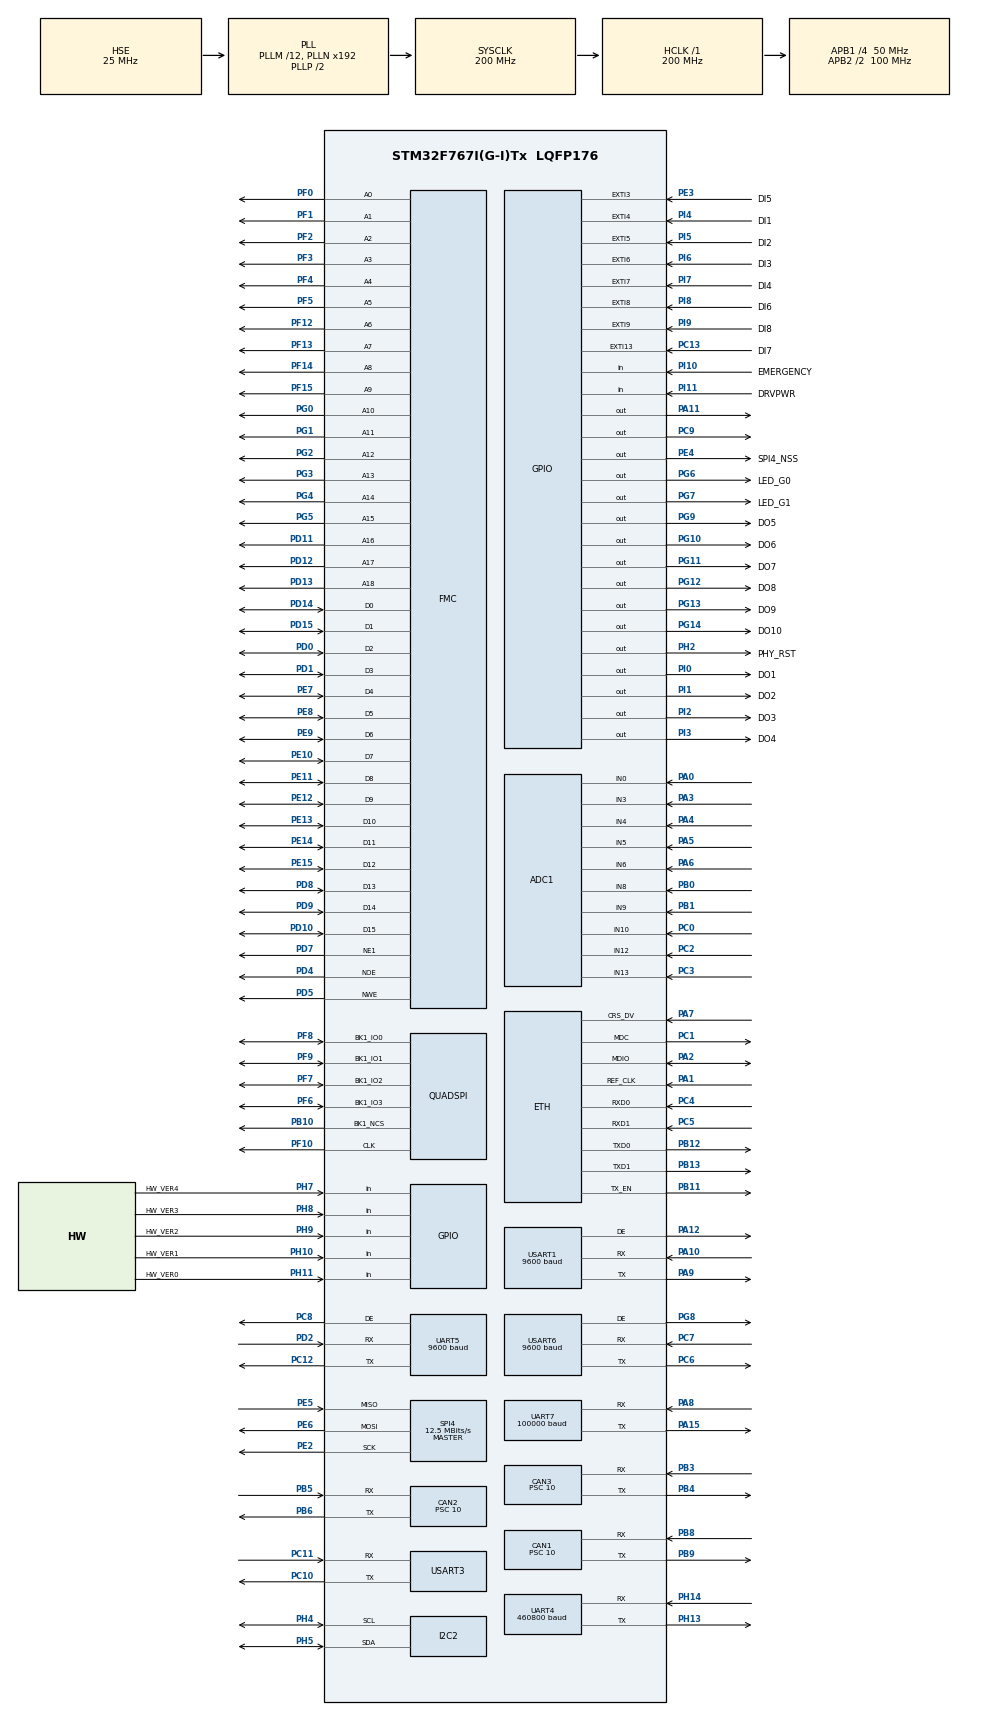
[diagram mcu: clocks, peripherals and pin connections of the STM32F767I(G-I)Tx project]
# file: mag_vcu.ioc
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ADC1.Channel-0\#ChannelRegularConversion=ADC_CHANNEL_13
ADC1.Channel-1\#ChannelRegularConversion=ADC_CHANNEL_0
ADC1.Channel-10\#ChannelRegularConversion=ADC_CHANNEL_TEMPSENSOR
ADC1.Channel-11\#ChannelRegularConversion=ADC_CHANNEL_VREFINT
ADC1.Channel-2\#ChannelRegularConversion=ADC_CHANNEL_10
ADC1.Channel-3\#ChannelRegularConversion=ADC_CHANNEL_12
ADC1.Channel-4\#ChannelRegularConversion=ADC_CHANNEL_5
ADC1.Channel-5\#ChannelRegularConversion=ADC_CHANNEL_6
ADC1.Channel-6\#ChannelRegularConversion=ADC_CHANNEL_3
ADC1.Channel-7\#ChannelRegularConversion=ADC_CHANNEL_4
ADC1.Channel-8\#ChannelRegularConversion=ADC_CHANNEL_8
ADC1.Channel-9\#ChannelRegularConversion=ADC_CHANNEL_9
ADC1.ContinuousConvMode=ENABLE
ADC1.DMAContinuousRequests=ENABLE
ADC1.EOCSelection=ADC_EOC_SEQ_CONV
ADC1.NbrOfConversion=12
ADC1.NbrOfConversionFlag=1
ADC1.Rank-0\#ChannelRegularConversion=1
ADC1.Rank-1\#ChannelRegularConversion=2
ADC1.Rank-10\#ChannelRegularConversion=11
ADC1.Rank-11\#ChannelRegularConversion=12
ADC1.Rank-2\#ChannelRegularConversion=3
ADC1.Rank-3\#ChannelRegularConversion=4
ADC1.Rank-4\#ChannelRegularConversion=5
ADC1.Rank-5\#ChannelRegularConversion=6
ADC1.Rank-6\#ChannelRegularConversion=7
ADC1.Rank-7\#ChannelRegularConversion=8
ADC1.Rank-8\#ChannelRegularConversion=9
ADC1.Rank-9\#ChannelRegularConversion=10
ADC1.SamplingTime-0\#ChannelRegularConversion=ADC_SAMPLETIME_56CYCLES
ADC1.SamplingTime-1\#ChannelRegularConversion=ADC_SAMPLETIME_56CYCLES
ADC1.SamplingTime-10\#ChannelRegularConversion=ADC_SAMPLETIME_56CYCLES
ADC1.SamplingTime-11\#ChannelRegularConversion=ADC_SAMPLETIME_56CYCLES
ADC1.SamplingTime-2\#ChannelRegularConversion=ADC_SAMPLETIME_56CYCLES
ADC1.SamplingTime-3\#ChannelRegularConversion=ADC_SAMPLETIME_56CYCLES
ADC1.SamplingTime-4\#ChannelRegularConversion=ADC_SAMPLETIME_56CYCLES
ADC1.SamplingTime-5\#ChannelRegularConversion=ADC_SAMPLETIME_56CYCLES
ADC1.SamplingTime-6\#ChannelRegularConversion=ADC_SAMPLETIME_56CYCLES
ADC1.SamplingTime-7\#ChannelRegularConversion=ADC_SAMPLETIME_56CYCLES
ADC1.SamplingTime-8\#ChannelRegularConversion=ADC_SAMPLETIME_56CYCLES
ADC1.SamplingTime-9\#ChannelRegularConversion=ADC_SAMPLETIME_56CYCLES
ADC1.ScanConvMode=ADC_SCAN_ENABLE
ADC1.master=1
CAN1.ABOM=ENABLE
CAN1.BS1=CAN_BS1_7TQ
CAN1.BS2=CAN_BS2_2TQ
CAN1.CalculateBaudRate=500000
CAN1.CalculateTimeBit=2000
CAN1.CalculateTimeQuantum=200.0
CAN1.NART=ENABLE
CAN1.Prescaler=10
CAN2.ABOM=ENABLE
CAN2.BS1=CAN_BS1_7TQ
CAN2.BS2=CAN_BS2_2TQ
CAN2.CalculateBaudRate=500000
CAN2.CalculateTimeBit=2000
CAN2.CalculateTimeQuantum=200.0
CAN2.NART=DISABLE
CAN2.Prescaler=10
CAN3.ABOM=ENABLE
CAN3.BS1=CAN_BS1_7TQ
CAN3.BS2=CAN_BS2_2TQ
CAN3.CalculateBaudRate=500000
CAN3.CalculateTimeBit=2000
CAN3.CalculateTimeQuantum=200.0
CAN3.NART=DISABLE
CAN3.Prescaler=10
CORTEX_M7.ART_ACCELERATOR_ENABLE=0
CORTEX_M7.AccessPermission-Cortex_Memory_Protection_Unit_Region0_Settings=MPU_REGION_FULL_ACCESS
CORTEX_M7.BaseAddress-Cortex_Memory_Protection_Unit_Region0_Settings=0x20020000
CORTEX_M7.CPU_DCache=Disabled
CORTEX_M7.CPU_ICache=Disabled
CORTEX_M7.Enable-Cortex_Memory_Protection_Unit_Region0_Settings=MPU_REGION_ENABLE
CORTEX_M7.IsBufferable-Cortex_Memory_Protection_Unit_Region0_Settings=MPU_ACCESS_NOT_BUFFERABLE
CORTEX_M7.IsCacheable-Cortex_Memory_Protection_Unit_Region0_Settings=MPU_ACCESS_CACHEABLE
CORTEX_M7.MPU_Control=__NULL
CORTEX_M7.Size-Cortex_Memory_Protection_Unit_Region0_Settings=MPU_REGION_SIZE_512KB
CORTEX_M7.TypeExtField-Cortex_Memory_Protection_Unit_Region0_Settings=MPU_TEX_LEVEL0
CORTEX_M7.default_mode_Activation=0
Dma.ADC1.3.Direction=DMA_PERIPH_TO_MEMORY
Dma.ADC1.3.FIFOMode=DMA_FIFOMODE_DISABLE
Dma.ADC1.3.Instance=DMA2_Stream0
Dma.ADC1.3.MemDataAlignment=DMA_MDATAALIGN_HALFWORD
Dma.ADC1.3.MemInc=DMA_MINC_ENABLE
Dma.ADC1.3.Mode=DMA_CIRCULAR
Dma.ADC1.3.PeriphDataAlignment=DMA_PDATAALIGN_HALFWORD
Dma.ADC1.3.PeriphInc=DMA_PINC_DISABLE
Dma.ADC1.3.Priority=DMA_PRIORITY_LOW
Dma.Request0=UART7_RX
Dma.Request1=USART3_RX
Dma.Request10=UART4_RX
Dma.Request2=USART3_TX
Dma.Request3=ADC1
Dma.Request4=USART6_RX
Dma.Request5=USART6_TX
Dma.Request6=USART1_RX
Dma.Request7=USART1_TX
Dma.Request8=UART5_RX
Dma.Request9=UART5_TX
Dma.UART4_RX.10.Direction=DMA_PERIPH_TO_MEMORY
Dma.UART4_RX.10.FIFOMode=DMA_FIFOMODE_DISABLE
Dma.UART4_RX.10.Instance=DMA1_Stream2
Dma.UART4_RX.10.MemDataAlignment=DMA_MDATAALIGN_BYTE
Dma.UART4_RX.10.MemInc=DMA_MINC_ENABLE
Dma.UART4_RX.10.Mode=DMA_NORMAL
Dma.UART4_RX.10.PeriphDataAlignment=DMA_PDATAALIGN_BYTE
Dma.UART4_RX.10.PeriphInc=DMA_PINC_DISABLE
Dma.UART4_RX.10.Priority=DMA_PRIORITY_LOW
Dma.UART5_RX.8.Direction=DMA_PERIPH_TO_MEMORY
Dma.UART5_RX.8.FIFOMode=DMA_FIFOMODE_DISABLE
Dma.UART5_RX.8.Instance=DMA1_Stream0
Dma.UART5_RX.8.MemDataAlignment=DMA_MDATAALIGN_BYTE
Dma.UART5_RX.8.MemInc=DMA_MINC_ENABLE
Dma.UART5_RX.8.Mode=DMA_NORMAL
Dma.UART5_RX.8.PeriphDataAlignment=DMA_PDATAALIGN_BYTE
Dma.UART5_RX.8.PeriphInc=DMA_PINC_DISABLE
Dma.UART5_RX.8.Priority=DMA_PRIORITY_LOW
Dma.UART5_TX.9.Direction=DMA_MEMORY_TO_PERIPH
Dma.UART5_TX.9.FIFOMode=DMA_FIFOMODE_DISABLE
Dma.UART5_TX.9.Instance=DMA1_Stream7
Dma.UART5_TX.9.MemDataAlignment=DMA_MDATAALIGN_BYTE
Dma.UART5_TX.9.MemInc=DMA_MINC_ENABLE
Dma.UART5_TX.9.Mode=DMA_NORMAL
Dma.UART5_TX.9.PeriphDataAlignment=DMA_PDATAALIGN_BYTE
Dma.UART5_TX.9.PeriphInc=DMA_PINC_DISABLE
Dma.UART5_TX.9.Priority=DMA_PRIORITY_LOW
Dma.UART7_RX.0.Direction=DMA_PERIPH_TO_MEMORY
Dma.UART7_RX.0.FIFOMode=DMA_FIFOMODE_DISABLE
Dma.UART7_RX.0.Instance=DMA1_Stream3
Dma.UART7_RX.0.MemDataAlignment=DMA_MDATAALIGN_BYTE
Dma.UART7_RX.0.MemInc=DMA_MINC_ENABLE
Dma.UART7_RX.0.Mode=DMA_NORMAL
Dma.UART7_RX.0.PeriphDataAlignment=DMA_PDATAALIGN_BYTE
Dma.UART7_RX.0.PeriphInc=DMA_PINC_DISABLE
Dma.UART7_RX.0.Priority=DMA_PRIORITY_LOW
Dma.USART1_RX.6.Direction=DMA_PERIPH_TO_MEMORY
Dma.USART1_RX.6.FIFOMode=DMA_FIFOMODE_DISABLE
Dma.USART1_RX.6.Instance=DMA2_Stream2
Dma.USART1_RX.6.MemDataAlignment=DMA_MDATAALIGN_BYTE
Dma.USART1_RX.6.MemInc=DMA_MINC_ENABLE
Dma.USART1_RX.6.Mode=DMA_NORMAL
Dma.USART1_RX.6.PeriphDataAlignment=DMA_PDATAALIGN_BYTE
Dma.USART1_RX.6.PeriphInc=DMA_PINC_DISABLE
Dma.USART1_RX.6.Priority=DMA_PRIORITY_LOW
Dma.USART1_TX.7.Direction=DMA_MEMORY_TO_PERIPH
Dma.USART1_TX.7.FIFOMode=DMA_FIFOMODE_DISABLE
Dma.USART1_TX.7.Instance=DMA2_Stream7
Dma.USART1_TX.7.MemDataAlignment=DMA_MDATAALIGN_BYTE
Dma.USART1_TX.7.MemInc=DMA_MINC_ENABLE
Dma.USART1_TX.7.Mode=DMA_NORMAL
Dma.USART1_TX.7.PeriphDataAlignment=DMA_PDATAALIGN_BYTE
Dma.USART1_TX.7.PeriphInc=DMA_PINC_DISABLE
Dma.USART1_TX.7.Priority=DMA_PRIORITY_LOW
Dma.USART3_RX.1.Direction=DMA_PERIPH_TO_MEMORY
Dma.USART3_RX.1.FIFOMode=DMA_FIFOMODE_DISABLE
Dma.USART3_RX.1.Instance=DMA1_Stream1
Dma.USART3_RX.1.MemDataAlignment=DMA_MDATAALIGN_BYTE
Dma.USART3_RX.1.MemInc=DMA_MINC_ENABLE
Dma.USART3_RX.1.Mode=DMA_NORMAL
Dma.USART3_RX.1.PeriphDataAlignment=DMA_PDATAALIGN_BYTE
Dma.USART3_RX.1.PeriphInc=DMA_PINC_DISABLE
Dma.USART3_RX.1.Priority=DMA_PRIORITY_LOW
Dma.USART3_TX.2.Direction=DMA_MEMORY_TO_PERIPH
Dma.USART3_TX.2.FIFOMode=DMA_FIFOMODE_DISABLE
Dma.USART3_TX.2.Instance=DMA1_Stream4
Dma.USART3_TX.2.MemDataAlignment=DMA_MDATAALIGN_BYTE
Dma.USART3_TX.2.MemInc=DMA_MINC_ENABLE
Dma.USART3_TX.2.Mode=DMA_NORMAL
Dma.USART3_TX.2.PeriphDataAlignment=DMA_PDATAALIGN_BYTE
Dma.USART3_TX.2.PeriphInc=DMA_PINC_DISABLE
Dma.USART3_TX.2.Priority=DMA_PRIORITY_LOW
Dma.USART6_RX.4.Direction=DMA_PERIPH_TO_MEMORY
Dma.USART6_RX.4.FIFOMode=DMA_FIFOMODE_DISABLE
Dma.USART6_RX.4.Instance=DMA2_Stream1
Dma.USART6_RX.4.MemDataAlignment=DMA_MDATAALIGN_BYTE
Dma.USART6_RX.4.MemInc=DMA_MINC_ENABLE
Dma.USART6_RX.4.Mode=DMA_NORMAL
Dma.USART6_RX.4.PeriphDataAlignment=DMA_PDATAALIGN_BYTE
Dma.USART6_RX.4.PeriphInc=DMA_PINC_DISABLE
Dma.USART6_RX.4.Priority=DMA_PRIORITY_LOW
Dma.USART6_TX.5.Direction=DMA_MEMORY_TO_PERIPH
Dma.USART6_TX.5.FIFOMode=DMA_FIFOMODE_DISABLE
Dma.USART6_TX.5.Instance=DMA2_Stream6
Dma.USART6_TX.5.MemDataAlignment=DMA_MDATAALIGN_BYTE
Dma.USART6_TX.5.MemInc=DMA_MINC_ENABLE
Dma.USART6_TX.5.Mode=DMA_NORMAL
Dma.USART6_TX.5.PeriphDataAlignment=DMA_PDATAALIGN_BYTE
Dma.USART6_TX.5.PeriphInc=DMA_PINC_DISABLE
Dma.USART6_TX.5.Priority=DMA_PRIORITY_LOW
ETH.ETH_RX_DESC_CNT=8
ETH.ETH_TX_DESC_CNT=8
ETH.MediaInterface=HAL_ETH_RMII_MODE
FMC.ExtendedAddressSetupTime1=5
FMC.ExtendedBusTurnAroundDuration1=3
FMC.ExtendedDataSetupTime1=3
FMC.ExtendedMode1=FMC_EXTENDED_MODE_ENABLE
FMC.WriteOperation1=FMC_WRITE_OPERATION_ENABLE
I2C2.Timing=0x00C0EAFF
IWDG.Prescaler=IWDG_PRESCALER_256
LPTIM1.ClockPrescaler=LPTIM_PRESCALER_DIV2
LPTIM1.UpdateMode=LPTIM_UPDATE_ENDOFPERIOD
Mcu.Family=STM32F7
Mcu.Name=STM32F767I(G-I)Tx
Mcu.Package=LQFP176
NVIC.ADC_IRQn=true\:5\:0\:true\:false\:true\:true\:true\:true
NVIC.CAN1_RX0_IRQn=true\:5\:0\:true\:false\:true\:true\:true\:true
NVIC.CAN1_TX_IRQn=true\:0\:0\:false\:false\:true\:true\:true\:true
NVIC.CAN2_RX0_IRQn=true\:5\:0\:true\:false\:true\:true\:true\:true
NVIC.CAN2_TX_IRQn=true\:0\:0\:false\:false\:true\:true\:true\:true
NVIC.CAN3_RX0_IRQn=true\:5\:0\:true\:false\:true\:true\:true\:true
NVIC.CAN3_TX_IRQn=true\:0\:0\:false\:false\:true\:true\:true\:true
NVIC.DMA1_Stream0_IRQn=true\:0\:0\:false\:false\:true\:false\:true\:true
NVIC.DMA1_Stream1_IRQn=true\:5\:0\:true\:false\:true\:false\:true\:true
NVIC.DMA1_Stream2_IRQn=true\:0\:0\:false\:false\:true\:false\:true\:true
NVIC.DMA1_Stream3_IRQn=true\:5\:0\:true\:false\:true\:false\:true\:true
NVIC.DMA1_Stream4_IRQn=true\:5\:0\:true\:false\:true\:false\:true\:true
NVIC.DMA1_Stream7_IRQn=true\:0\:0\:false\:false\:true\:false\:true\:true
NVIC.DMA2_Stream0_IRQn=true\:5\:0\:true\:false\:true\:false\:true\:true
NVIC.DMA2_Stream1_IRQn=true\:5\:0\:true\:false\:true\:false\:true\:true
NVIC.DMA2_Stream2_IRQn=true\:5\:0\:true\:false\:true\:false\:true\:true
NVIC.DMA2_Stream6_IRQn=true\:5\:0\:true\:false\:true\:false\:true\:true
NVIC.DMA2_Stream7_IRQn=true\:5\:0\:true\:false\:true\:false\:true\:true
NVIC.ETH_IRQn=true\:5\:0\:true\:false\:true\:true\:true\:true
NVIC.EXTI15_10_IRQn=true\:0\:0\:false\:false\:true\:true\:true\:true
NVIC.EXTI3_IRQn=true\:0\:0\:false\:false\:true\:true\:true\:true
NVIC.EXTI4_IRQn=true\:0\:0\:false\:false\:true\:true\:true\:true
NVIC.EXTI9_5_IRQn=true\:0\:0\:false\:false\:true\:true\:true\:true
NVIC.I2C2_EV_IRQn=true\:5\:0\:true\:false\:true\:true\:true\:true
NVIC.PriorityGroup=NVIC_PRIORITYGROUP_4
NVIC.QUADSPI_IRQn=true\:5\:0\:true\:false\:true\:true\:true\:true
NVIC.SPI4_IRQn=true\:5\:0\:true\:false\:true\:true\:true\:true
NVIC.TIM1_UP_TIM10_IRQn=true\:5\:0\:true\:false\:true\:true\:true\:true
NVIC.TIM6_DAC_IRQn=true\:15\:0\:true\:false\:true\:false\:true\:true
NVIC.TimeBase=TIM6_DAC_IRQn
NVIC.TimeBaseIP=TIM6
NVIC.UART4_IRQn=true\:5\:0\:true\:false\:true\:true\:true\:true
NVIC.UART5_IRQn=true\:0\:0\:false\:false\:true\:true\:true\:true
NVIC.UART7_IRQn=true\:5\:0\:true\:false\:true\:true\:true\:true
NVIC.USART1_IRQn=true\:5\:0\:true\:false\:true\:true\:true\:true
NVIC.USART3_IRQn=true\:5\:0\:true\:false\:true\:true\:true\:true
NVIC.USART6_IRQn=true\:5\:0\:true\:false\:true\:true\:true\:true
PA0/WKUP.Signal=ADCx_IN0
PA1.GPIO_PuPd=GPIO_PULLUP
PA1.Mode=RMII
PA1.Signal=ETH_REF_CLK
PA10.Mode=Asynchronous
PA10.Signal=USART1_RX
PA11.GPIO_ModeDefaultOutputPP=GPIO_MODE_OUTPUT_OD
PA11.GPIO_PuPd=GPIO_NOPULL
PA11.PinState=GPIO_PIN_SET
PA11.Signal=GPIO_Output
PA12.GPIO_PuPd=GPIO_PULLUP
PA12.Mode=Hardware Flow Control (RS485)
PA12.Signal=USART1_DE
PA13.Mode=Serial_Wire
PA13.Signal=SYS_JTMS-SWDIO
PA14.Mode=Serial_Wire
PA14.Signal=SYS_JTCK-SWCLK
PA15.GPIO_PuPd=GPIO_PULLUP
PA15.Mode=Asynchronous
PA15.Signal=UART7_TX
PA2.Mode=RMII
PA2.Signal=ETH_MDIO
PA3.Signal=ADCx_IN3
PA4.Signal=ADCx_IN4
PA5.Signal=ADCx_IN5
PA6.Signal=ADCx_IN6
PA7.GPIO_PuPd=GPIO_PULLUP
PA7.Mode=RMII
PA7.Signal=ETH_CRS_DV
PA8.Mode=Asynchronous
PA8.Signal=UART7_RX
PA9.GPIO_PuPd=GPIO_PULLUP
PA9.Mode=Asynchronous
PA9.Signal=USART1_TX
PB0.Signal=ADCx_IN8
PB1.Signal=ADCx_IN9
PB10.GPIO_PuPd=GPIO_NOPULL
PB10.Mode=Single Bank 1
PB10.Signal=QUADSPI_BK1_NCS
PB11.GPIO_PuPd=GPIO_PULLUP
PB11.Mode=RMII
PB11.Signal=ETH_TX_EN
PB12.GPIO_PuPd=GPIO_PULLUP
PB12.Mode=RMII
PB12.Signal=ETH_TXD0
PB13.GPIO_PuPd=GPIO_PULLUP
PB13.Mode=RMII
PB13.Signal=ETH_TXD1
PB3.Mode=CAN_Activate
PB3.Signal=CAN3_RX
PB4.GPIO_PuPd=GPIO_PULLUP
PB4.Mode=CAN_Activate
PB4.Signal=CAN3_TX
PB5.Mode=CAN_Activate
PB5.Signal=CAN2_RX
PB6.GPIO_PuPd=GPIO_PULLUP
PB6.Mode=CAN_Activate
PB6.Signal=CAN2_TX
PB8.Mode=CAN_Activate
PB8.Signal=CAN1_RX
PB9.GPIO_PuPd=GPIO_PULLUP
PB9.Mode=CAN_Activate
PB9.Signal=CAN1_TX
PC0.Signal=ADCx_IN10
PC1.GPIO_PuPd=GPIO_PULLUP
PC1.Mode=RMII
PC1.Signal=ETH_MDC
PC10.GPIO_PuPd=GPIO_PULLUP
PC10.Mode=Asynchronous
PC10.Signal=USART3_TX
PC11.Mode=Asynchronous
PC11.Signal=USART3_RX
PC12.GPIO_PuPd=GPIO_PULLUP
PC12.Mode=Asynchronous
PC12.Signal=UART5_TX
PC13.GPIO_Label=DI7
PC13.GPIO_ModeDefaultEXTI=GPIO_MODE_IT_RISING_FALLING
PC13.Signal=GPXTI13
PC14/OSC32_IN.Mode=LSE-External-Oscillator
PC14/OSC32_IN.Signal=RCC_OSC32_IN
PC15/OSC32_OUT.Mode=LSE-External-Oscillator
PC15/OSC32_OUT.Signal=RCC_OSC32_OUT
PC2.Signal=ADCx_IN12
PC3.Signal=ADCx_IN13
PC4.Mode=RMII
PC4.Signal=ETH_RXD0
PC5.Mode=RMII
PC5.Signal=ETH_RXD1
PC6.GPIO_PuPd=GPIO_PULLUP
PC6.Mode=Asynchronous
PC6.Signal=USART6_TX
PC7.Mode=Asynchronous
PC7.Signal=USART6_RX
PC8.GPIO_PuPd=GPIO_PULLUP
PC8.Mode=Hardware Flow Control (RS485)
PC8.Signal=UART5_DE
PC9.GPIO_ModeDefaultOutputPP=GPIO_MODE_OUTPUT_OD
PC9.GPIO_PuPd=GPIO_NOPULL
PC9.PinState=GPIO_PIN_SET
PC9.Signal=GPIO_Output
PD0.Signal=FMC_D2_DA2
PD1.Signal=FMC_D3_DA3
PD10.Signal=FMC_D15_DA15
PD11.Signal=FMC_A16_CLE
PD12.Signal=FMC_A17_ALE
PD13.Signal=FMC_A18
PD14.Signal=FMC_D0_DA0
PD15.Signal=FMC_D1_DA1
PD2.Mode=Asynchronous
PD2.Signal=UART5_RX
PD4.Signal=FMC_NOE
PD5.Signal=FMC_NWE
PD7.Mode=NorPsramChipSelect1_1
PD7.Signal=FMC_NE1
PD8.Signal=FMC_D13_DA13
PD9.Signal=FMC_D14_DA14
PE10.Signal=FMC_D7_DA7
PE11.Signal=FMC_D8_DA8
PE12.Signal=FMC_D9_DA9
PE13.Signal=FMC_D10_DA10
PE14.Signal=FMC_D11_DA11
PE15.Signal=FMC_D12_DA12
PE2.GPIO_PuPd=GPIO_NOPULL
PE2.Mode=Full_Duplex_Master
PE2.Signal=SPI4_SCK
PE3.GPIO_Label=DI5
PE3.GPIO_ModeDefaultEXTI=GPIO_MODE_IT_RISING_FALLING
PE3.Signal=GPXTI3
PE4.GPIO_Label=SPI4_NSS
PE4.GPIO_ModeDefaultOutputPP=GPIO_MODE_OUTPUT_PP
PE4.GPIO_PuPd=GPIO_NOPULL
PE4.GPIO_Speed=GPIO_SPEED_FREQ_VERY_HIGH
PE4.PinState=GPIO_PIN_SET
PE4.Signal=GPIO_Output
PE5.Mode=Full_Duplex_Master
PE5.Signal=SPI4_MISO
PE6.GPIO_PuPd=GPIO_NOPULL
PE6.Mode=Full_Duplex_Master
PE6.Signal=SPI4_MOSI
PE7.Signal=FMC_D4_DA4
PE8.Signal=FMC_D5_DA5
PE9.Signal=FMC_D6_DA6
PF0.Signal=FMC_A0
PF1.Signal=FMC_A1
PF10.GPIO_PuPd=GPIO_PULLUP
PF10.Mode=Single Bank 1
PF10.Signal=QUADSPI_CLK
PF12.Signal=FMC_A6
PF13.Signal=FMC_A7
PF14.Signal=FMC_A8
PF15.Signal=FMC_A9
PF2.Signal=FMC_A2
PF3.Signal=FMC_A3
PF4.Signal=FMC_A4
PF5.Signal=FMC_A5
PF6.GPIO_PuPd=GPIO_PULLUP
PF6.Mode=Single Bank 1
PF6.Signal=QUADSPI_BK1_IO3
PF7.GPIO_PuPd=GPIO_PULLUP
PF7.Mode=Single Bank 1
PF7.Signal=QUADSPI_BK1_IO2
PF8.GPIO_PuPd=GPIO_PULLUP
PF8.Mode=Single Bank 1
PF8.Signal=QUADSPI_BK1_IO0
PF9.GPIO_PuPd=GPIO_PULLUP
PF9.Mode=Single Bank 1
PF9.Signal=QUADSPI_BK1_IO1
PG0.Signal=FMC_A10
PG1.Signal=FMC_A11
PG10.GPIO_Label=DO6
PG10.Signal=GPIO_Output
PG11.GPIO_Label=DO7
PG11.Signal=GPIO_Output
PG12.GPIO_Label=DO8
PG12.Signal=GPIO_Output
PG13.GPIO_Label=DO9
PG13.PinState=GPIO_PIN_SET
PG13.Signal=GPIO_Output
PG14.GPIO_Label=DO10
PG14.PinState=GPIO_PIN_SET
PG14.Signal=GPIO_Output
PG2.Signal=FMC_A12
PG3.Signal=FMC_A13
PG4.Signal=FMC_A14_BA0
PG5.Signal=FMC_A15_BA1
PG6.GPIO_Label=LED_G0
PG6.GPIO_ModeDefaultOutputPP=GPIO_MODE_OUTPUT_OD
PG6.GPIO_PuPd=GPIO_NOPULL
PG6.PinState=GPIO_PIN_SET
PG6.Signal=GPIO_Output
PG7.GPIO_Label=LED_G1
PG7.GPIO_ModeDefaultOutputPP=GPIO_MODE_OUTPUT_OD
PG7.GPIO_PuPd=GPIO_NOPULL
PG7.PinState=GPIO_PIN_SET
PG7.Signal=GPIO_Output
PG8.GPIO_PuPd=GPIO_PULLUP
PG8.Mode=Hardware Flow Control (RS485)
PG8.Signal=USART6_DE
PG9.GPIO_Label=DO5
PG9.Signal=GPIO_Output
PH0/OSC_IN.Mode=HSE-External-Oscillator
PH0/OSC_IN.Signal=RCC_OSC_IN
PH1/OSC_OUT.Mode=HSE-External-Oscillator
PH1/OSC_OUT.Signal=RCC_OSC_OUT
PH10.GPIO_Label=HW_VER1
PH10.Signal=GPIO_Input
PH11.GPIO_Label=HW_VER0
PH11.Signal=GPIO_Input
PH13.GPIO_PuPd=GPIO_PULLUP
PH13.Mode=Asynchronous
PH13.Signal=UART4_TX
PH14.Mode=Asynchronous
PH14.Signal=UART4_RX
PH2.GPIO_Label=PHY_RST
PH2.GPIO_ModeDefaultOutputPP=GPIO_MODE_OUTPUT_OD
PH2.GPIO_PuPd=GPIO_NOPULL
PH2.PinState=GPIO_PIN_SET
PH2.Signal=GPIO_Output
PH4.Mode=I2C
PH4.Signal=I2C2_SCL
PH5.Mode=I2C
PH5.Signal=I2C2_SDA
PH7.GPIO_Label=HW_VER4
PH7.Signal=GPIO_Input
PH8.GPIO_Label=HW_VER3
PH8.Signal=GPIO_Input
PH9.GPIO_Label=HW_VER2
PH9.Signal=GPIO_Input
PI0.GPIO_Label=DO1
PI0.GPIO_ModeDefaultOutputPP=GPIO_MODE_OUTPUT_OD
PI0.GPIO_PuPd=GPIO_NOPULL
PI0.PinState=GPIO_PIN_SET
PI0.Signal=GPIO_Output
PI1.GPIO_Label=DO2
PI1.GPIO_ModeDefaultOutputPP=GPIO_MODE_OUTPUT_OD
PI1.GPIO_PuPd=GPIO_NOPULL
PI1.PinState=GPIO_PIN_RESET
PI1.Signal=GPIO_Output
PI10.GPIO_Label=EMERGENCY
PI10.Signal=GPIO_Input
PI11.GPIO_Label=DRVPWR
PI11.Signal=GPIO_Input
PI2.GPIO_Label=DO3
PI2.GPIO_ModeDefaultOutputPP=GPIO_MODE_OUTPUT_OD
PI2.GPIO_PuPd=GPIO_NOPULL
PI2.PinState=GPIO_PIN_SET
PI2.Signal=GPIO_Output
PI3.GPIO_Label=DO4
PI3.GPIO_ModeDefaultOutputPP=GPIO_MODE_OUTPUT_OD
PI3.GPIO_PuPd=GPIO_NOPULL
PI3.PinState=GPIO_PIN_SET
PI3.Signal=GPIO_Output
PI4.GPIO_Label=DI1
PI4.GPIO_ModeDefaultEXTI=GPIO_MODE_IT_RISING_FALLING
PI4.Signal=GPXTI4
PI5.GPIO_Label=DI2
PI5.GPIO_ModeDefaultEXTI=GPIO_MODE_IT_RISING_FALLING
PI5.Signal=GPXTI5
PI6.GPIO_Label=DI3
PI6.GPIO_ModeDefaultEXTI=GPIO_MODE_IT_RISING_FALLING
PI6.Signal=GPXTI6
PI7.GPIO_Label=DI4
PI7.GPIO_ModeDefaultEXTI=GPIO_MODE_IT_RISING_FALLING
PI7.Signal=GPXTI7
PI8.GPIO_Label=DI6
PI8.GPIO_ModeDefaultEXTI=GPIO_MODE_IT_RISING_FALLING
PI8.Signal=GPXTI8
PI9.GPIO_Label=DI8
PI9.GPIO_ModeDefaultEXTI=GPIO_MODE_IT_RISING_FALLING
PI9.Signal=GPXTI9
ProjectManager.HeapSize=0x200
ProjectManager.StackSize=0x6000
ProjectManager.TargetToolchain=CMake
QUADSPI.ChipSelectHighTime=QSPI_CS_HIGH_TIME_6_CYCLE
QUADSPI.ClockPrescaler=4
QUADSPI.FifoThreshold=4
QUADSPI.FlashSize=24-1
QUADSPI.SampleShifting=QSPI_SAMPLE_SHIFTING_HALFCYCLE
RCC.AHBFreq_Value=200000000
RCC.APB1CLKDivider=RCC_HCLK_DIV4
RCC.APB1Freq_Value=50000000
RCC.APB1TimFreq_Value=100000000
RCC.APB2CLKDivider=RCC_HCLK_DIV2
RCC.APB2Freq_Value=100000000
RCC.APB2TimFreq_Value=200000000
RCC.CortexFreq_Value=200000000
RCC.HCLKFreq_Value=200000000
RCC.HSE_VALUE=25000000
RCC.HSI_VALUE=16000000
RCC.PLLM=12
RCC.PLLQ=9
RCC.PLLSourceVirtual=RCC_PLLSOURCE_HSE
RCC.SYSCLKFreq_VALUE=200000000
RCC.SYSCLKSource=RCC_SYSCLKSOURCE_PLLCLK
RCC.USBFreq_Value=44444444.44444445
RCC.VCOOutputFreq_Value=400000000
SH.ADCx_IN0.0=ADC1_IN0,IN0
SH.ADCx_IN10.0=ADC1_IN10,IN10
SH.ADCx_IN12.0=ADC1_IN12,IN12
SH.ADCx_IN13.0=ADC1_IN13,IN13
SH.ADCx_IN3.0=ADC1_IN3,IN3
SH.ADCx_IN4.0=ADC1_IN4,IN4
SH.ADCx_IN5.0=ADC1_IN5,IN5
SH.ADCx_IN6.0=ADC1_IN6,IN6
SH.ADCx_IN8.0=ADC1_IN8,IN8
SH.ADCx_IN9.0=ADC1_IN9,IN9
SH.FMC_A0.0=FMC_A0,19b-a1
SH.FMC_A1.0=FMC_A1,19b-a1
SH.FMC_A10.0=FMC_A10,19b-a1
SH.FMC_A11.0=FMC_A11,19b-a1
SH.FMC_A12.0=FMC_A12,19b-a1
SH.FMC_A13.0=FMC_A13,19b-a1
SH.FMC_A14_BA0.0=FMC_A14,19b-a1
SH.FMC_A15_BA1.0=FMC_A15,19b-a1
SH.FMC_A16_CLE.0=FMC_A16,19b-a1
SH.FMC_A17_ALE.0=FMC_A17,19b-a1
SH.FMC_A18.0=FMC_A18,19b-a1
SH.FMC_A2.0=FMC_A2,19b-a1
SH.FMC_A3.0=FMC_A3,19b-a1
SH.FMC_A4.0=FMC_A4,19b-a1
SH.FMC_A5.0=FMC_A5,19b-a1
SH.FMC_A6.0=FMC_A6,19b-a1
SH.FMC_A7.0=FMC_A7,19b-a1
SH.FMC_A8.0=FMC_A8,19b-a1
SH.FMC_A9.0=FMC_A9,19b-a1
SH.FMC_D0_DA0.0=FMC_D0,16b-d1
SH.FMC_D10_DA10.0=FMC_D10,16b-d1
SH.FMC_D11_DA11.0=FMC_D11,16b-d1
SH.FMC_D12_DA12.0=FMC_D12,16b-d1
SH.FMC_D13_DA13.0=FMC_D13,16b-d1
SH.FMC_D14_DA14.0=FMC_D14,16b-d1
SH.FMC_D15_DA15.0=FMC_D15,16b-d1
SH.FMC_D1_DA1.0=FMC_D1,16b-d1
SH.FMC_D2_DA2.0=FMC_D2,16b-d1
SH.FMC_D3_DA3.0=FMC_D3,16b-d1
SH.FMC_D4_DA4.0=FMC_D4,16b-d1
SH.FMC_D5_DA5.0=FMC_D5,16b-d1
SH.FMC_D6_DA6.0=FMC_D6,16b-d1
SH.FMC_D7_DA7.0=FMC_D7,16b-d1
SH.FMC_D8_DA8.0=FMC_D8,16b-d1
SH.FMC_D9_DA9.0=FMC_D9,16b-d1
SH.FMC_NOE.0=FMC_NOE,Sram1
SH.FMC_NWE.0=FMC_NWE,Sram1
SPI4.BaudRatePrescaler=SPI_BAUDRATEPRESCALER_8
SPI4.CLKPhase=SPI_PHASE_2EDGE
SPI4.CLKPolarity=SPI_POLARITY_HIGH
SPI4.CalculateBaudRate=12.5 MBits/s
SPI4.DataSize=SPI_DATASIZE_8BIT
SPI4.Direction=SPI_DIRECTION_2LINES
SPI4.Mode=SPI_MODE_MASTER
SPI4.VirtualType=VM_MASTER
STMicroelectronics.X-CUBE-ALGOBUILD.1.3.0.LibraryCcDSPOoLibraryJjDSPOoLibrary=true
TIM1.AutoReloadPreload=TIM_AUTORELOAD_PRELOAD_ENABLE
TIM1.ClockDivision=TIM_CLOCKDIVISION_DIV2
TIM1.Period=100
TIM1.Prescaler=100-1
TIM2.AutoReloadPreload=TIM_AUTORELOAD_PRELOAD_ENABLE
TIM2.Period=1000000
TIM2.Prescaler=100-1
TIM2.TIM_MasterOutputTrigger=TIM_TRGO_UPDATE
TIM2.TIM_MasterSlaveMode=TIM_MASTERSLAVEMODE_ENABLE
UART4.BaudRate=460800
UART5.BaudRate=9600
UART7.BaudRate=100000
UART7.DMADisableonRxErrorParam=UART_ADVFEATURE_DMA_ENABLEONRXERROR
UART7.Mode=MODE_RX
UART7.OverrunDisableParam=UART_ADVFEATURE_OVERRUN_ENABLE
UART7.Parity=PARITY_EVEN
UART7.StopBits=UART_STOPBITS_2
UART7.WordLength=WORDLENGTH_9B
USART1.BaudRate=9600
USART1.VirtualMode-Asynchronous=VM_ASYNC
USART1.VirtualMode-Hardware\ Flow\ Control\ (RS485)=VM_ASYNC
USART3.VirtualMode-Asynchronous=VM_ASYNC
USART6.BaudRate=9600
USART6.VirtualMode-Asynchronous=VM_ASYNC
USART6.VirtualMode-Hardware\ Flow\ Control\ (RS485)=VM_ASYNC
VP_ADC1_TempSens_Input.Mode=IN-TempSens
VP_ADC1_Vref_Input.Mode=IN-Vrefint
VP_CRC_VS_CRC.Mode=CRC_Activate
VP_IWDG_VS_IWDG.Mode=IWDG_Activate
VP_LPTIM1_VS_LPTIM_counterModeInternalClock.Mode=Counts__internal_clock_event_00
VP_RNG_VS_RNG.Mode=RNG_Activate
VP_STMicroelectronics.X-CUBE-ALGOBUILD_VS_DSPOoLibraryJjLibrary_1.3.0_1.3.0.Mode=DSPOoLibraryJjLibrary
VP_SYS_VS_tim6.Mode=TIM6
VP_TIM1_VS_ClockSourceINT.Mode=Internal
VP_TIM2_VS_ClockSourceINT.Mode=Internal
VP_TIM5_VS_ClockSourceITR.Mode=TriggerSource_ITR0
VP_TIM5_VS_ControllerModeClock.Mode=Clock Mode
board=custom

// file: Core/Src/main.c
/* USER CODE BEGIN Header */
/**
  ******************************************************************************
  * @file           : main.c
  * @brief          : Main program body
  ******************************************************************************
  * @attention
  *
  * Copyright (c) 2025 STMicroelectronics.
  * All rights reserved.
  *
  * This software is licensed under terms that can be found in the LICENSE file
  * in the root directory of this software component.
  * If no LICENSE file comes with this software, it is provided AS-IS.
  *
  ******************************************************************************
  */
/* USER CODE END Header */
#include "main.h"
#include "adc.h"
#include "can.h"
#include "crc.h"
#include "dma.h"
#include "eth.h"
#include "i2c.h"
#include "iwdg.h"
#include "lptim.h"
#include "quadspi.h"
#include "rng.h"
#include "spi.h"
#include "tim.h"
#include "tx_api.h"
#include "usart.h"
#include "gpio.h"
#include "fmc.h"

/* USER CODE BEGIN Includes */
#include "tx_thread.h"
#include "tx_initialize.h"
#include "thread_init.h"
#include "flash_nor.h"
/* USER CODE END Includes */

/* USER CODE BEGIN PTD */
uint32_t HAL_GetTick (void)
{
static uint32_t ticks = 0U;
uint32_t i;
if (TX_THREAD_GET_SYSTEM_STATE() == TX_INITIALIZE_IS_FINISHED)
{
return ((uint32_t)_tx_time_get());
}
/* ??ThreadX?????,?????? */
for (i = (SystemCoreClock >> 14U); i > 0U; i--)
{
__NOP(); __NOP(); __NOP(); __NOP(); __NOP(); __NOP();
__NOP(); __NOP(); __NOP(); __NOP(); __NOP(); __NOP();
}
return ++ticks;
}

void sleep_s(uint32_t s)
{
  tx_thread_sleep(s*1000);
}
void sleep_ms(uint32_t ms)
{
	tx_thread_sleep(ms);
}
void sleep_us(uint32_t us)
{
	tx_thread_sleep(us/1000u);
}

/* USER CODE END PTD */

void SystemClock_Config(void);

/* USER CODE BEGIN 0 */
// thread init
TX_THREAD thread_init_block;
#define THREAD_INIT_STACK_SIZE 				4096u
uint64_t thread_init_stack[THREAD_INIT_STACK_SIZE/8];
#define THREAD_INIT_PRIO							28u

/******************************tx kits define**************************************/

// pool

// sem
TX_SEMAPHORE  sem_socket_connected;

static void tx_pool_create(void)
{

}

static void tx_sem_create(void)
{
  tx_semaphore_create(&sem_socket_connected, "sem_socket_connected", 0);
}

void  tx_application_define(void *first_unused_memory)
{
  norflash_init();
	tx_pool_create();
  tx_sem_create();

  tx_thread_create(&thread_init_block,
                  "init",
                  thread_init,
                  0,
                  &thread_init_stack[0],
                  THREAD_INIT_STACK_SIZE,
                  THREAD_INIT_PRIO,
                  THREAD_INIT_PRIO,
                  TX_NO_TIME_SLICE,
                  TX_AUTO_START);
}
/* USER CODE END 0 */

int main(void)
{

  /* MCU Configuration--------------------------------------------------------*/

  /* Reset of all peripherals, Initializes the Flash interface and the Systick. */
  HAL_Init();

  /* Configure the system clock */
  SystemClock_Config();

  /* Initialize all configured peripherals */
  MX_GPIO_Init();
  MX_DMA_Init();
  MX_CAN1_Init();
  MX_CAN2_Init();
  MX_CAN3_Init();
  MX_I2C2_Init();
  MX_SPI4_Init();
  MX_UART4_Init();
  MX_UART5_Init();
  MX_UART7_Init();
  MX_USART1_UART_Init();
  MX_USART3_UART_Init();
  MX_USART6_UART_Init();
  MX_RNG_Init();
  MX_TIM2_Init();
  MX_ADC1_Init();
  MX_TIM5_Init();
  MX_QUADSPI_Init();
  MX_TIM1_Init();
  MX_ETH_Init();
  MX_FMC_Init();
  MX_LPTIM1_Init();
  MX_CRC_Init();
  // MX_IWDG_Init();
  /* USER CODE BEGIN 2 */
  tx_kernel_enter();

  /* USER CODE END 2 */

  /* Infinite loop */
  while (1)
  {

  }
}

void SystemClock_Config(void)
{
  RCC_OscInitTypeDef RCC_OscInitStruct = {0};
  RCC_ClkInitTypeDef RCC_ClkInitStruct = {0};

  /** Configure LSE Drive Capability
  */
  HAL_PWR_EnableBkUpAccess();

  /** Configure the main internal regulator output voltage
  */
  __HAL_RCC_PWR_CLK_ENABLE();
  __HAL_PWR_VOLTAGESCALING_CONFIG(PWR_REGULATOR_VOLTAGE_SCALE1);

  /** Initializes the RCC Oscillators according to the specified parameters
  * in the RCC_OscInitTypeDef structure.
  */
  RCC_OscInitStruct.OscillatorType = RCC_OSCILLATORTYPE_LSI|RCC_OSCILLATORTYPE_HSE;
  RCC_OscInitStruct.HSEState = RCC_HSE_ON;
  RCC_OscInitStruct.LSIState = RCC_LSI_ON;
  RCC_OscInitStruct.PLL.PLLState = RCC_PLL_ON;
  RCC_OscInitStruct.PLL.PLLSource = RCC_PLLSOURCE_HSE;
  RCC_OscInitStruct.PLL.PLLM = 12;
  RCC_OscInitStruct.PLL.PLLN = 192;
  RCC_OscInitStruct.PLL.PLLP = RCC_PLLP_DIV2;
  RCC_OscInitStruct.PLL.PLLQ = 9;
  RCC_OscInitStruct.PLL.PLLR = 2;
  if (HAL_RCC_OscConfig(&RCC_OscInitStruct) != HAL_OK)
  {
    Error_Handler();
  }

  /** Activate the Over-Drive mode
  */
  if (HAL_PWREx_EnableOverDrive() != HAL_OK)
  {
    Error_Handler();
  }

  /** Initializes the CPU, AHB and APB buses clocks
  */
  RCC_ClkInitStruct.ClockType = RCC_CLOCKTYPE_HCLK|RCC_CLOCKTYPE_SYSCLK
                              |RCC_CLOCKTYPE_PCLK1|RCC_CLOCKTYPE_PCLK2;
  RCC_ClkInitStruct.SYSCLKSource = RCC_SYSCLKSOURCE_PLLCLK;
  RCC_ClkInitStruct.AHBCLKDivider = RCC_SYSCLK_DIV1;
  RCC_ClkInitStruct.APB1CLKDivider = RCC_HCLK_DIV4;
  RCC_ClkInitStruct.APB2CLKDivider = RCC_HCLK_DIV2;

  if (HAL_RCC_ClockConfig(&RCC_ClkInitStruct, FLASH_LATENCY_6) != HAL_OK)
  {
    Error_Handler();
  }
}

void HAL_TIM_PeriodElapsedCallback(TIM_HandleTypeDef *htim)
{
  if (htim->Instance == TIM6)
  {
    HAL_IncTick();
  }
}

void Error_Handler(void)
{
  __disable_irq();
  while (1)
  {
  }
}
